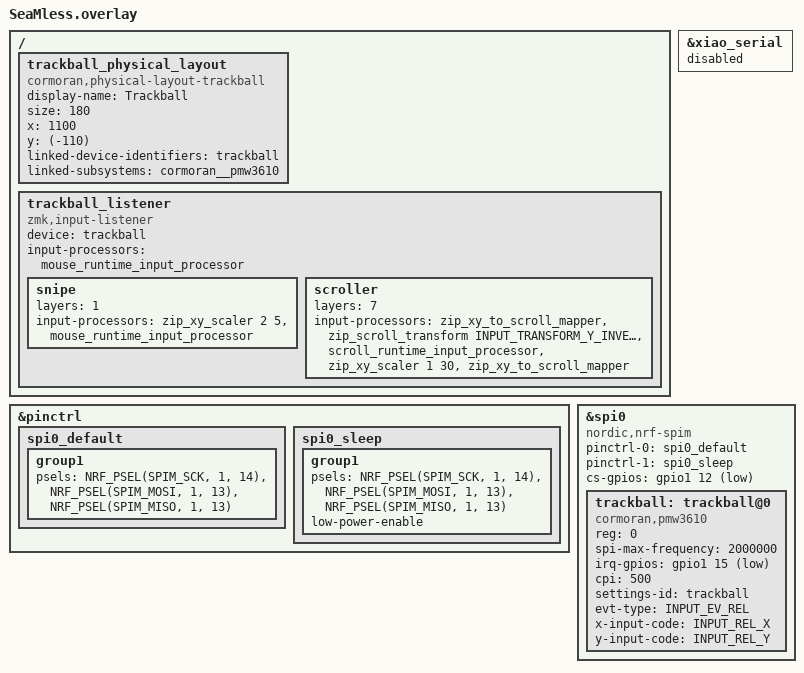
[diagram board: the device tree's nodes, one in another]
#include "SeaMless.dtsi"
#include <input/processors.dtsi>
#include <input/processors/runtime-input-processor.dtsi>
#include <dt-bindings/zmk/input_transform.h>
#include <zephyr/dt-bindings/input/input-event-codes.h>
#include <behaviors/battery_history_request.dtsi>

/ {
    trackball_physical_layout: trackball_physical_layout {
        compatible = "cormoran,physical-layout-trackball";
        display-name = "Trackball";
        size = <180>;
        x = <1100>;
        y = <(-110)>;
        linked-device-identifiers = "trackball";
        linked-subsystems = "cormoran__pmw3610";
    };

    trackball_listener {
        compatible = "zmk,input-listener";
        device = <&trackball>;
        input-processors = <&mouse_runtime_input_processor>;
        snipe {
            layers = <1>;
            input-processors = <&zip_xy_scaler 2 5 &mouse_runtime_input_processor>;
        };
        scroller {
            layers = <7>;
            input-processors = <&zip_xy_to_scroll_mapper
                                &zip_scroll_transform INPUT_TRANSFORM_Y_INVERT
                                &scroll_runtime_input_processor
                                &zip_xy_scaler 1 30
                                &zip_xy_to_scroll_mapper>;
        };
    };
};

&pinctrl {
    spi0_default: spi0_default {
        group1 {
            psels = <NRF_PSEL(SPIM_SCK, 1, 14)>,
                    <NRF_PSEL(SPIM_MOSI, 1, 13)>,
                    <NRF_PSEL(SPIM_MISO, 1, 13)>;
        };
    };

    spi0_sleep: spi0_sleep {
        group1 {
            psels = <NRF_PSEL(SPIM_SCK, 1, 14)>,
                    <NRF_PSEL(SPIM_MOSI, 1, 13)>,
                    <NRF_PSEL(SPIM_MISO, 1, 13)>;
            low-power-enable;
        };
    };
};

&xiao_serial {
    status = "disabled";
};

&spi0 {
    status = "okay";
    compatible = "nordic,nrf-spim";
    pinctrl-0 = <&spi0_default>;
    pinctrl-1 = <&spi0_sleep>;
    pinctrl-names = "default", "sleep";
    cs-gpios = <&gpio1 12 GPIO_ACTIVE_LOW>;

    trackball: trackball@0 {
        status = "okay";
        compatible = "cormoran,pmw3610";
        reg = <0>;
        spi-max-frequency = <2000000>;
        irq-gpios = <&gpio1 15 (GPIO_ACTIVE_LOW | GPIO_PULL_UP)>;
        cpi = <500>;
        settings-id = "trackball";
        evt-type = <INPUT_EV_REL>;
        x-input-code = <INPUT_REL_X>;
        y-input-code = <INPUT_REL_Y>;
    };
};
